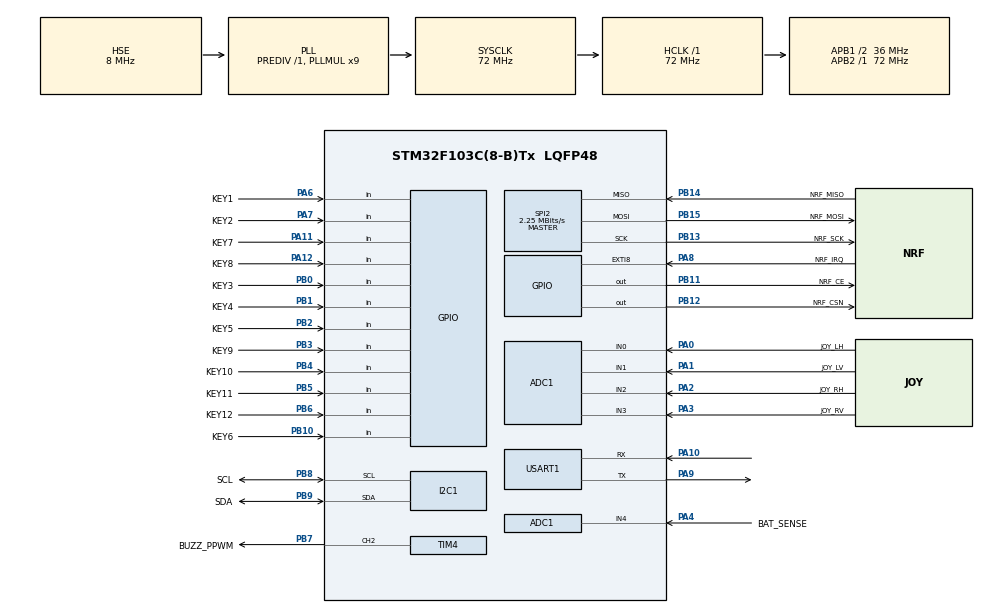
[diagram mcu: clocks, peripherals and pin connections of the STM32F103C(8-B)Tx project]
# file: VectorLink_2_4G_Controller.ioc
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ADC1.Channel-0\#ChannelRegularConversion=ADC_CHANNEL_0
ADC1.Channel-1\#ChannelRegularConversion=ADC_CHANNEL_1
ADC1.Channel-2\#ChannelRegularConversion=ADC_CHANNEL_2
ADC1.Channel-3\#ChannelRegularConversion=ADC_CHANNEL_3
ADC1.Channel-4\#ChannelRegularConversion=ADC_CHANNEL_4
ADC1.ContinuousConvMode=ENABLE
ADC1.NbrOfConversion=5
ADC1.NbrOfConversionFlag=1
ADC1.Rank-0\#ChannelRegularConversion=1
ADC1.Rank-1\#ChannelRegularConversion=2
ADC1.Rank-2\#ChannelRegularConversion=3
ADC1.Rank-3\#ChannelRegularConversion=4
ADC1.Rank-4\#ChannelRegularConversion=5
ADC1.SamplingTime-0\#ChannelRegularConversion=ADC_SAMPLETIME_55CYCLES_5
ADC1.SamplingTime-1\#ChannelRegularConversion=ADC_SAMPLETIME_55CYCLES_5
ADC1.SamplingTime-2\#ChannelRegularConversion=ADC_SAMPLETIME_55CYCLES_5
ADC1.SamplingTime-3\#ChannelRegularConversion=ADC_SAMPLETIME_55CYCLES_5
ADC1.SamplingTime-4\#ChannelRegularConversion=ADC_SAMPLETIME_239CYCLES_5
ADC1.master=1
Dma.ADC1.0.Direction=DMA_PERIPH_TO_MEMORY
Dma.ADC1.0.Instance=DMA1_Channel1
Dma.ADC1.0.MemDataAlignment=DMA_MDATAALIGN_HALFWORD
Dma.ADC1.0.MemInc=DMA_MINC_ENABLE
Dma.ADC1.0.Mode=DMA_CIRCULAR
Dma.ADC1.0.PeriphDataAlignment=DMA_PDATAALIGN_HALFWORD
Dma.ADC1.0.PeriphInc=DMA_PINC_DISABLE
Dma.ADC1.0.Priority=DMA_PRIORITY_LOW
Dma.Request0=ADC1
FREERTOS.INCLUDE_uxTaskGetStackHighWaterMark2=1
FREERTOS.Tasks01=defaultTask,24,128,StartDefaultTask,Default,NULL,Dynamic,NULL,NULL
FREERTOS.configCHECK_FOR_STACK_OVERFLOW=2
FREERTOS.configRECORD_STACK_HIGH_ADDRESS=1
FREERTOS.configTOTAL_HEAP_SIZE=8192
I2C1.I2C_Mode=I2C_Fast
Mcu.Family=STM32F1
Mcu.Name=STM32F103C(8-B)Tx
Mcu.Package=LQFP48
NVIC.DMA1_Channel1_IRQn=true\:5\:0\:true\:false\:true\:true\:false\:true\:true
NVIC.EXTI9_5_IRQn=true\:5\:0\:true\:false\:true\:true\:true\:true\:true
NVIC.PriorityGroup=NVIC_PRIORITYGROUP_4
NVIC.TIM2_IRQn=true\:15\:0\:false\:false\:true\:false\:false\:true\:true
NVIC.TimeBase=TIM2_IRQn
NVIC.TimeBaseIP=TIM2
PA0-WKUP.GPIO_Label=JOY_LH
PA0-WKUP.Signal=ADCx_IN0
PA1.GPIO_Label=JOY_LV
PA1.Signal=ADCx_IN1
PA10.Mode=Asynchronous
PA10.Signal=USART1_RX
PA11.GPIO_Label=KEY7
PA11.GPIO_PuPd=GPIO_PULLUP
PA11.Signal=GPIO_Input
PA12.GPIO_Label=KEY8
PA12.GPIO_PuPd=GPIO_PULLUP
PA12.Signal=GPIO_Input
PA13.Mode=Serial_Wire
PA13.Signal=SYS_JTMS-SWDIO
PA14.Mode=Serial_Wire
PA14.Signal=SYS_JTCK-SWCLK
PA2.GPIO_Label=JOY_RH
PA2.Signal=ADCx_IN2
PA3.GPIO_Label=JOY_RV
PA3.Signal=ADCx_IN3
PA4.GPIO_Label=BAT_SENSE
PA4.Signal=ADCx_IN4
PA6.GPIO_Label=KEY1
PA6.GPIO_PuPd=GPIO_PULLUP
PA6.Signal=GPIO_Input
PA7.GPIO_Label=KEY2
PA7.GPIO_PuPd=GPIO_PULLUP
PA7.Signal=GPIO_Input
PA8.GPIO_Label=NRF_IRQ
PA8.GPIO_ModeDefaultEXTI=GPIO_MODE_IT_FALLING
PA8.GPIO_PuPd=GPIO_NOPULL
PA8.Signal=GPXTI8
PA9.Mode=Asynchronous
PA9.Signal=USART1_TX
PB0.GPIO_Label=KEY3
PB0.GPIO_PuPd=GPIO_PULLUP
PB0.Signal=GPIO_Input
PB1.GPIO_Label=KEY4
PB1.GPIO_PuPd=GPIO_PULLUP
PB1.Signal=GPIO_Input
PB10.GPIO_Label=KEY6
PB10.GPIO_PuPd=GPIO_PULLUP
PB10.Signal=GPIO_Input
PB11.GPIO_Label=NRF_CE
PB11.GPIO_PuPd=GPIO_NOPULL
PB11.GPIO_Speed=GPIO_SPEED_FREQ_HIGH
PB11.Signal=GPIO_Output
PB12.GPIO_Label=NRF_CSN
PB12.GPIO_Speed=GPIO_SPEED_FREQ_HIGH
PB12.PinState=GPIO_PIN_SET
PB12.Signal=GPIO_Output
PB13.GPIO_Label=NRF_SCK
PB13.Mode=Full_Duplex_Master
PB13.Signal=SPI2_SCK
PB14.GPIO_Label=NRF_MISO
PB14.Mode=Full_Duplex_Master
PB14.Signal=SPI2_MISO
PB15.GPIO_Label=NRF_MOSI
PB15.Mode=Full_Duplex_Master
PB15.Signal=SPI2_MOSI
PB2.GPIO_Label=KEY5
PB2.GPIO_PuPd=GPIO_PULLUP
PB2.Signal=GPIO_Input
PB3.GPIO_Label=KEY9
PB3.GPIO_PuPd=GPIO_PULLUP
PB3.Signal=GPIO_Input
PB4.GPIO_Label=KEY10
PB4.GPIO_PuPd=GPIO_PULLUP
PB4.Signal=GPIO_Input
PB5.GPIO_Label=KEY11
PB5.GPIO_PuPd=GPIO_PULLUP
PB5.Signal=GPIO_Input
PB6.GPIO_Label=KEY12
PB6.GPIO_PuPd=GPIO_PULLUP
PB6.Signal=GPIO_Input
PB7.GPIO_Label=BUZZ_PPWM
PB7.Signal=S_TIM4_CH2
PB8.GPIO_Label=SCL
PB8.Mode=I2C
PB8.Signal=I2C1_SCL
PB9.GPIO_Label=SDA
PB9.Mode=I2C
PB9.Signal=I2C1_SDA
PD0-OSC_IN.Mode=HSE-External-Oscillator
PD0-OSC_IN.Signal=RCC_OSC_IN
PD1-OSC_OUT.Mode=HSE-External-Oscillator
PD1-OSC_OUT.Signal=RCC_OSC_OUT
ProjectManager.HeapSize=0x200
ProjectManager.StackSize=0x400
ProjectManager.TargetToolchain=MDK-ARM V5.32
RCC.ADCPresc=RCC_ADCPCLK2_DIV6
RCC.AHBFreq_Value=72000000
RCC.APB1CLKDivider=RCC_HCLK_DIV2
RCC.APB1Freq_Value=36000000
RCC.APB1TimFreq_Value=72000000
RCC.APB2Freq_Value=72000000
RCC.APB2TimFreq_Value=72000000
RCC.HCLKFreq_Value=72000000
RCC.PLLMUL=RCC_PLL_MUL9
RCC.PLLSourceVirtual=RCC_PLLSOURCE_HSE
RCC.SYSCLKFreq_VALUE=72000000
RCC.SYSCLKSource=RCC_SYSCLKSOURCE_PLLCLK
RCC.USBFreq_Value=72000000
SH.ADCx_IN0.0=ADC1_IN0,IN0
SH.ADCx_IN1.0=ADC1_IN1,IN1
SH.ADCx_IN2.0=ADC1_IN2,IN2
SH.ADCx_IN3.0=ADC1_IN3,IN3
SH.ADCx_IN4.0=ADC1_IN4,IN4
SH.S_TIM4_CH2.0=TIM4_CH2,PWM Generation2 CH2
SPI2.BaudRatePrescaler=SPI_BAUDRATEPRESCALER_16
SPI2.CalculateBaudRate=2.25 MBits/s
SPI2.Direction=SPI_DIRECTION_2LINES
SPI2.Mode=SPI_MODE_MASTER
SPI2.VirtualType=VM_MASTER
TIM4.AutoReloadPreload=TIM_AUTORELOAD_PRELOAD_ENABLE
TIM4.Channel-PWM\ Generation2\ CH2=TIM_CHANNEL_2
TIM4.Period=416-1
TIM4.Prescaler=71
TIM4.Pulse-PWM\ Generation2\ CH2=208
USART1.VirtualMode=VM_ASYNC
VP_FREERTOS_VS_CMSIS_V2.Mode=CMSIS_V2
VP_SYS_VS_tim2.Mode=TIM2
VP_TIM4_VS_ClockSourceINT.Mode=Internal
board=custom

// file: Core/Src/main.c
/* USER CODE BEGIN Header */
/**
  ******************************************************************************
  * @file           : main.c
  * @brief          : Main program body
  ******************************************************************************
  * @attention
  *
  * Copyright (c) 2026 STMicroelectronics.
  * All rights reserved.
  *
  * This software is licensed under terms that can be found in the LICENSE file
  * in the root directory of this software component.
  * If no LICENSE file comes with this software, it is provided AS-IS.
  *
  ******************************************************************************
  */
/* USER CODE END Header */
#include "main.h"
#include "cmsis_os.h"
#include "adc.h"
#include "dma.h"
#include "i2c.h"
#include "spi.h"
#include "tim.h"
#include "usart.h"
#include "gpio.h"

void SystemClock_Config(void);
void MX_FREERTOS_Init(void);

int main(void)
{

  /* MCU Configuration--------------------------------------------------------*/

  /* Reset of all peripherals, Initializes the Flash interface and the Systick. */
  HAL_Init();

  /* Configure the system clock */
  SystemClock_Config();

  /* Initialize all configured peripherals */
  MX_GPIO_Init();
  MX_DMA_Init();
  MX_USART1_UART_Init();
  MX_ADC1_Init();
  MX_I2C1_Init();
  MX_SPI2_Init();
  MX_TIM4_Init();

  /* Init scheduler */
  osKernelInitialize();  /* Call init function for freertos objects (in cmsis_os2.c) */
  MX_FREERTOS_Init();

  /* Start scheduler */
  osKernelStart();

  /* We should never get here as control is now taken by the scheduler */

  /* Infinite loop */
  while (1)
  {

  }
}

void SystemClock_Config(void)
{
  RCC_OscInitTypeDef RCC_OscInitStruct = {0};
  RCC_ClkInitTypeDef RCC_ClkInitStruct = {0};
  RCC_PeriphCLKInitTypeDef PeriphClkInit = {0};

  /** Initializes the RCC Oscillators according to the specified parameters
  * in the RCC_OscInitTypeDef structure.
  */
  RCC_OscInitStruct.OscillatorType = RCC_OSCILLATORTYPE_HSE;
  RCC_OscInitStruct.HSEState = RCC_HSE_ON;
  RCC_OscInitStruct.HSEPredivValue = RCC_HSE_PREDIV_DIV1;
  RCC_OscInitStruct.HSIState = RCC_HSI_ON;
  RCC_OscInitStruct.PLL.PLLState = RCC_PLL_ON;
  RCC_OscInitStruct.PLL.PLLSource = RCC_PLLSOURCE_HSE;
  RCC_OscInitStruct.PLL.PLLMUL = RCC_PLL_MUL9;
  if (HAL_RCC_OscConfig(&RCC_OscInitStruct) != HAL_OK)
  {
    Error_Handler();
  }

  /** Initializes the CPU, AHB and APB buses clocks
  */
  RCC_ClkInitStruct.ClockType = RCC_CLOCKTYPE_HCLK|RCC_CLOCKTYPE_SYSCLK
                              |RCC_CLOCKTYPE_PCLK1|RCC_CLOCKTYPE_PCLK2;
  RCC_ClkInitStruct.SYSCLKSource = RCC_SYSCLKSOURCE_PLLCLK;
  RCC_ClkInitStruct.AHBCLKDivider = RCC_SYSCLK_DIV1;
  RCC_ClkInitStruct.APB1CLKDivider = RCC_HCLK_DIV2;
  RCC_ClkInitStruct.APB2CLKDivider = RCC_HCLK_DIV1;

  if (HAL_RCC_ClockConfig(&RCC_ClkInitStruct, FLASH_LATENCY_2) != HAL_OK)
  {
    Error_Handler();
  }
  PeriphClkInit.PeriphClockSelection = RCC_PERIPHCLK_ADC;
  PeriphClkInit.AdcClockSelection = RCC_ADCPCLK2_DIV6;
  if (HAL_RCCEx_PeriphCLKConfig(&PeriphClkInit) != HAL_OK)
  {
    Error_Handler();
  }
}

void HAL_TIM_PeriodElapsedCallback(TIM_HandleTypeDef *htim)
{
  if (htim->Instance == TIM2)
  {
    HAL_IncTick();
  }
}

void Error_Handler(void)
{
  __disable_irq();
  while (1)
  {
  }
}

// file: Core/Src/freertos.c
/* USER CODE BEGIN Header */
/**
  ******************************************************************************
  * File Name          : freertos.c
  * Description        : Code for freertos applications
  ******************************************************************************
  * @attention
  *
  * Copyright (c) 2026 STMicroelectronics.
  * All rights reserved.
  *
  * This software is licensed under terms that can be found in the LICENSE file
  * in the root directory of this software component.
  * If no LICENSE file comes with this software, it is provided AS-IS.
  *
  ******************************************************************************
  */
/* USER CODE END Header */

#include "FreeRTOS.h"
#include "task.h"
#include "main.h"
#include "cmsis_os.h"

/* USER CODE BEGIN Includes */
#include "app_main.h"

/* USER CODE END Includes */

/* Definitions for defaultTask */
osThreadId_t defaultTaskHandle;
const osThreadAttr_t defaultTask_attributes = {
  .name = "defaultTask",
  .stack_size = 128 * 4,
  .priority = (osPriority_t) osPriorityNormal,
};

/* USER CODE BEGIN FunctionPrototypes */
void vApplicationMallocFailedHook(void);

/* USER CODE END FunctionPrototypes */

void StartDefaultTask(void *argument);

void MX_FREERTOS_Init(void); /* (MISRA C 2004 rule 8.1) */

/* Hook prototypes */
void vApplicationStackOverflowHook(xTaskHandle xTask, signed char *pcTaskName);

/* USER CODE BEGIN 4 */
void vApplicationMallocFailedHook(void)
{
  taskDISABLE_INTERRUPTS();
  while (1)
  {
  }
}

void vApplicationStackOverflowHook(xTaskHandle xTask, signed char* pcTaskName)
{
  /* Run time stack overflow checking is performed if
     configCHECK_FOR_STACK_OVERFLOW is defined to 1 or 2. This hook function is
     called if a stack overflow is detected. */
  (void)xTask;
  (void)pcTaskName;
  taskDISABLE_INTERRUPTS();
  while (1)
  {
  }
}
/* USER CODE END 4 */

void MX_FREERTOS_Init(void) {

  /* Create the thread(s) */
  /* creation of defaultTask */
  defaultTaskHandle = osThreadNew(StartDefaultTask, NULL, &defaultTask_attributes);

  /* USER CODE BEGIN RTOS_THREADS */
  VectorLink_InitializeApp();
  /* USER CODE END RTOS_THREADS */

}

void StartDefaultTask(void *argument)
{
  /* USER CODE BEGIN StartDefaultTask */
  vTaskDelete(NULL);
  /* USER CODE END StartDefaultTask */
}
